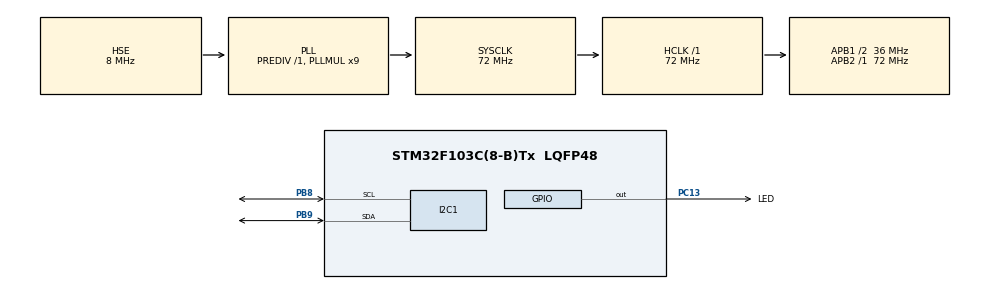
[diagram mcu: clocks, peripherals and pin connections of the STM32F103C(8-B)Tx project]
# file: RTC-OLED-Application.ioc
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I2C1.I2C_Mode=I2C_Fast
Mcu.Family=STM32F1
Mcu.Name=STM32F103C(8-B)Tx
Mcu.Package=LQFP48
NVIC.PriorityGroup=NVIC_PRIORITYGROUP_4
PA13.Mode=Serial_Wire
PA13.Signal=SYS_JTMS-SWDIO
PA14.Mode=Serial_Wire
PA14.Signal=SYS_JTCK-SWCLK
PB8.Mode=I2C
PB8.Signal=I2C1_SCL
PB9.Mode=I2C
PB9.Signal=I2C1_SDA
PC13-TAMPER-RTC.GPIO_Label=LED
PC13-TAMPER-RTC.Signal=GPIO_Output
PD0-OSC_IN.Mode=HSE-External-Oscillator
PD0-OSC_IN.Signal=RCC_OSC_IN
PD1-OSC_OUT.Mode=HSE-External-Oscillator
PD1-OSC_OUT.Signal=RCC_OSC_OUT
ProjectManager.HeapSize=0x200
ProjectManager.StackSize=0x400
ProjectManager.TargetToolchain=SW4STM32
RCC.AHBFreq_Value=72000000
RCC.APB1CLKDivider=RCC_HCLK_DIV2
RCC.APB1Freq_Value=36000000
RCC.APB1TimFreq_Value=72000000
RCC.APB2Freq_Value=72000000
RCC.APB2TimFreq_Value=72000000
RCC.HCLKFreq_Value=72000000
RCC.PLLMUL=RCC_PLL_MUL9
RCC.PLLSourceVirtual=RCC_PLLSOURCE_HSE
RCC.SYSCLKFreq_VALUE=72000000
RCC.SYSCLKSource=RCC_SYSCLKSOURCE_PLLCLK
RCC.USBFreq_Value=72000000
RTC.Format=RTC_FORMAT_BIN
VP_RTC_No_RTC_Output.Mode=RTC_OUT_NO
VP_RTC_VS_RTC_Activate.Mode=RTC_Enabled
VP_RTC_VS_RTC_Calendar.Mode=RTC_Calendar
board=custom

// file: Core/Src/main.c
/* USER CODE BEGIN Header */
/**
  ******************************************************************************
  * @file           : main.c
  * @brief          : Main program body
  ******************************************************************************
  * @attention
  *
  * <h2><center>&copy; Copyright (c) 2020 STMicroelectronics.
  * All rights reserved.</center></h2>
  *
  * This software component is licensed by ST under BSD 3-Clause license,
  * the "License"; You may not use this file except in compliance with the
  * License. You may obtain a copy of the License at:
  *                        opensource.org/licenses/BSD-3-Clause
  *
  ******************************************************************************
  */
/* USER CODE END Header */
#include "main.h"
#include "i2c.h"
#include "rtc.h"
#include "gpio.h"

/* USER CODE BEGIN Includes */
#include "ssd1306.h"
#include <stdio.h>

/* USER CODE END Includes */

/* USER CODE BEGIN PV */
RTC_HandleTypeDef rtcHandle;
RTC_TimeTypeDef currentTime;
RTC_DateTypeDef currentDate;

/* USER CODE END PV */

void SystemClock_Config(void);

/* USER CODE BEGIN 0 */
void RTC_Config(void);
void RTC_TimeDate_Config(void);

/* USER CODE END 0 */

int main(void)
{
  /* USER CODE BEGIN 1 */
  char data[30];
  char horario[30];

  /* USER CODE END 1 */

  /* MCU Configuration--------------------------------------------------------*/

  /* Reset of all peripherals, Initializes the Flash interface and the Systick. */
  HAL_Init();

  /* Configure the system clock */
  SystemClock_Config();

  /* Initialize all configured peripherals */
  MX_GPIO_Init();
  MX_I2C1_Init();
  MX_RTC_Init();
  /* USER CODE BEGIN 2 */
  SSD1306_Init();
  RTC_Config();
  RTC_TimeDate_Config();

  /* USER CODE END 2 */

  /* Infinite loop */
  while (1)
  {
		HAL_RTC_GetTime(&rtcHandle, &currentTime, RTC_FORMAT_BIN);
		HAL_RTC_GetDate(&rtcHandle, &currentDate, RTC_FORMAT_BIN);

		/* Print current date and time (date time format: yyyy-MM-dd hh:mm:ss)*/
		sprintf(data, "%0*i-%0*i-20%i", 2, currentDate.Date, 2, currentDate.Month, currentDate.Year);
		SSD1306_GotoXY (0,0);
		SSD1306_Puts (data, &Font_11x18, 1);
		SSD1306_UpdateScreen(); // update display

		sprintf(horario, "H:%0*i:%0*i:%0*i", 2, currentTime.Hours, 2, currentTime.Minutes, 2, currentTime.Seconds);
		SSD1306_GotoXY (0,30);
		SSD1306_Puts (horario, &Font_11x18, 1);
		SSD1306_UpdateScreen(); // update display
		HAL_Delay(1000);
  }
  /* USER CODE END 3 */
}

void SystemClock_Config(void)
{
  RCC_OscInitTypeDef RCC_OscInitStruct = {0};
  RCC_ClkInitTypeDef RCC_ClkInitStruct = {0};
  RCC_PeriphCLKInitTypeDef PeriphClkInit = {0};

  /** Initializes the RCC Oscillators according to the specified parameters
  * in the RCC_OscInitTypeDef structure.
  */
  RCC_OscInitStruct.OscillatorType = RCC_OSCILLATORTYPE_LSI|RCC_OSCILLATORTYPE_HSE;
  RCC_OscInitStruct.HSEState = RCC_HSE_ON;
  RCC_OscInitStruct.HSEPredivValue = RCC_HSE_PREDIV_DIV1;
  RCC_OscInitStruct.HSIState = RCC_HSI_ON;
  RCC_OscInitStruct.LSIState = RCC_LSI_ON;
  RCC_OscInitStruct.PLL.PLLState = RCC_PLL_ON;
  RCC_OscInitStruct.PLL.PLLSource = RCC_PLLSOURCE_HSE;
  RCC_OscInitStruct.PLL.PLLMUL = RCC_PLL_MUL9;
  if (HAL_RCC_OscConfig(&RCC_OscInitStruct) != HAL_OK)
  {
    Error_Handler();
  }
  /** Initializes the CPU, AHB and APB buses clocks
  */
  RCC_ClkInitStruct.ClockType = RCC_CLOCKTYPE_HCLK|RCC_CLOCKTYPE_SYSCLK
                              |RCC_CLOCKTYPE_PCLK1|RCC_CLOCKTYPE_PCLK2;
  RCC_ClkInitStruct.SYSCLKSource = RCC_SYSCLKSOURCE_PLLCLK;
  RCC_ClkInitStruct.AHBCLKDivider = RCC_SYSCLK_DIV1;
  RCC_ClkInitStruct.APB1CLKDivider = RCC_HCLK_DIV2;
  RCC_ClkInitStruct.APB2CLKDivider = RCC_HCLK_DIV1;

  if (HAL_RCC_ClockConfig(&RCC_ClkInitStruct, FLASH_LATENCY_2) != HAL_OK)
  {
    Error_Handler();
  }
  PeriphClkInit.PeriphClockSelection = RCC_PERIPHCLK_RTC;
  PeriphClkInit.RTCClockSelection = RCC_RTCCLKSOURCE_LSI;
  if (HAL_RCCEx_PeriphCLKConfig(&PeriphClkInit) != HAL_OK)
  {
    Error_Handler();
  }
}

/* USER CODE BEGIN 4 */
/**
  * @brief  RTC configuration
  * @param  None
  * @retval None
  */
void RTC_Config(void)
{
	/*## STEP 1: Configure RTC ###############################################*/
	rtcHandle.Instance          = RTC;
	rtcHandle.Init.AsynchPrediv = RTC_AUTO_1_SECOND;
	rtcHandle.Init.OutPut       = RTC_OUTPUTSOURCE_NONE;
	if (HAL_RTC_Init(&rtcHandle) != HAL_OK)
	{
		Error_Handler();
	}
}

/**
  * @brief  Time and date configuration
  * @param  None
  * @retval None
  */
void RTC_TimeDate_Config(void)
{
	RTC_TimeTypeDef rtcTimeStruct;
	RTC_DateTypeDef rtcDateStruct;

	/*## STEP 1: Configure time ##############################################*/
	/* Set time: 23:59:55 */
	rtcTimeStruct.Hours   = 0x23;
	rtcTimeStruct.Minutes = 0x59;
	rtcTimeStruct.Seconds = 0x48;
	if (HAL_RTC_SetTime(&rtcHandle, &rtcTimeStruct, RTC_FORMAT_BCD) != HAL_OK)
	{
		Error_Handler();
	}

	/*## STEP 2: Configure date ##############################################*/
	/* Set date: 17/02/2020 */
	rtcDateStruct.Year    = 0x20;
	rtcDateStruct.Month   = RTC_MONTH_FEBRUARY;
	rtcDateStruct.Date    = 0x17;
	rtcDateStruct.WeekDay = RTC_WEEKDAY_MONDAY;
	if(HAL_RTC_SetDate(&rtcHandle, &rtcDateStruct, RTC_FORMAT_BCD) != HAL_OK)
	{
		Error_Handler();
	}
}
/* USER CODE END 4 */

void Error_Handler(void)
{
}

/************************ (C) COPYRIGHT STMicroelectronics *****END OF FILE****/
